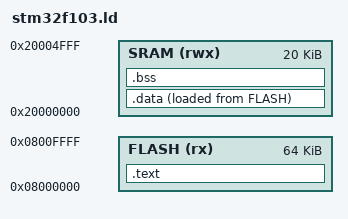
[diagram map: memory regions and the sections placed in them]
/* STM32F103C8 Linker Script */
/* 64KB Flash, 20KB SRAM */

MEMORY
{
    FLASH (rx)  : ORIGIN = 0x08000000, LENGTH = 64K
    SRAM (rwx)  : ORIGIN = 0x20000000, LENGTH = 20K
}

ENTRY(Reset_Handler)

SECTIONS
{
    .text :
    {
        . = ALIGN(4);
        _stext = .;
        *(.text)
        *(.text*)
        *(.rodata)
        *(.rodata*)
        _etext = .;
    } > FLASH

    .data :
    {
        . = ALIGN(4);
        _sdata = .;
        *(.data)
        *(.data*)
        _edata = .;
    } > SRAM AT > FLASH

    .bss :
    {
        . = ALIGN(4);
        _sbss = .;
        *(.bss)
        *(.bss*)
        *(COMMON)
        _ebss = .;
    } > SRAM

    _end = .;

    /DISCARD/ :
    {
        libc.a (*)
        libm.a (*)
        libgcc.a (*)
    }
}
